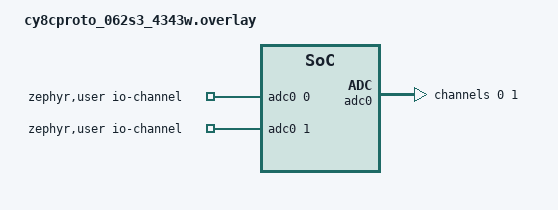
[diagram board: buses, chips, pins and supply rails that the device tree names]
/*
 * SPDX-FileCopyrightText: Copyright (c) 2026 Infineon Technologies AG,
 * SPDX-FileCopyrightText: or an affiliate of Infineon Technologies AG. All rights reserved.
 *
 * SPDX-License-Identifier: Apache-2.0
 */

#include <zephyr/dt-bindings/adc/adc.h>

/ {
	zephyr,user {
		io-channels = <&adc0 0>, <&adc0 1>;
	};
};

&adc0 {
	#address-cells = <1>;
	#size-cells = <0>;
	status = "okay";

	channel@0 {
		reg = <0>;
		zephyr,acquisition-time = <ADC_ACQ_TIME(ADC_ACQ_TIME_MICROSECONDS, 1)>;
		zephyr,gain = "ADC_GAIN_1";
		zephyr,reference = "ADC_REF_INTERNAL";
		zephyr,resolution = <12>;
		zephyr,input-positive = <2>;   /* P10.2 */
	};

	channel@1 {
		reg = <1>;
		zephyr,acquisition-time = <ADC_ACQ_TIME(ADC_ACQ_TIME_MICROSECONDS, 1)>;
		zephyr,gain = "ADC_GAIN_1";
		zephyr,reference = "ADC_REF_INTERNAL";
		zephyr,resolution = <12>;
		zephyr,input-positive = <3>;   /* P10.3 */
	};
};
